# CTRL_MODULE_WKUP register map
Vendor: Texas Instruments
Peripheral module from a debugger description file (folder omap5430_ES2_PUBLIC).
Registers are 32-bit, access per field, reset 0x0 unless marked. A register's access mark holds for its fields unless they carry their own. Offsets are as the file gives them; lines under a group give offsets from that group; [hi:lo] are bit positions; {n}, {i} and the like mark numbered series; 'fields as' and 'values as' point back to an identical list; <NAME> marks a mode.

## CTRL_MODULE_WKUP
0x00 CONTROL_WKUP_REVISION ro reset not defined — Control module revision identifier Access conditions. Read: unrestricted, Write: unrestricted
  [31:0] REVISON — IP Revision . .
0x04 CONTROL_WKUP_HWINFO ro — Information about the IP module hardware configuration i.e. typically the module HDL generics (if any). Access conditions. Read: unrestricted, Write: unrestricted
  [31:0] IP_HWINFO — IP-module dependent
0x10 CONTROL_WKUP_SYSCONFIG reset 0x8 — Access conditions. Read: unrestricted, Write: unrestricted
  [3:2] IP_SYSCONFIG_IDLEMODE rw — RESERVED (not used).
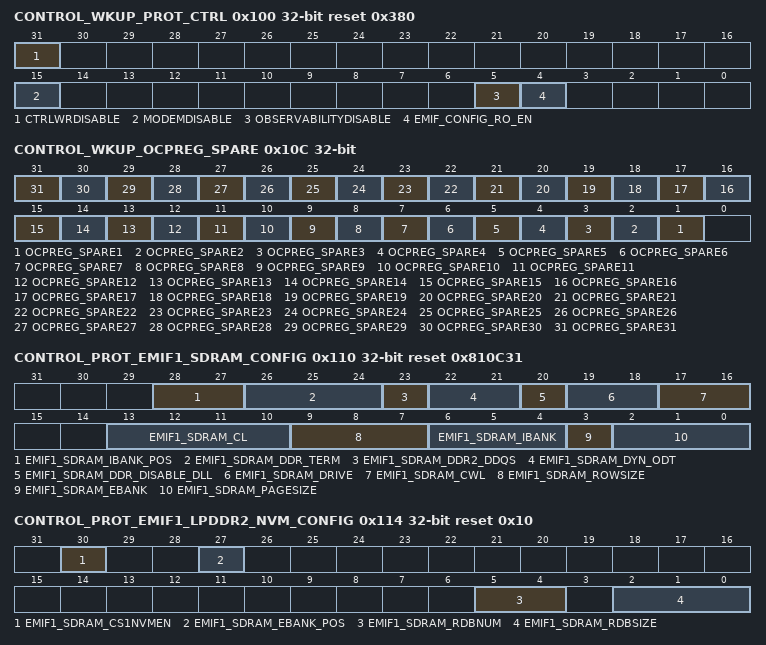
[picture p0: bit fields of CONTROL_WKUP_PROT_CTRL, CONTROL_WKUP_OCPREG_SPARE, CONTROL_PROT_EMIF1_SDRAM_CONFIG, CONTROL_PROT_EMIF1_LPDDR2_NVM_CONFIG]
0x100 CONTROL_WKUP_PROT_CTRL access not given reset 0x380 — Control Register. Access conditions. Read: unrestricted, Write: unrestricted
  [31] CTRLWRDISABLE — Control Register write disable control. (access RW Woco)
    0=wr_allowed (Write in the Control Register is allowed); 1=wr_forbidden (Write in the Control Register is forbidden)
  [15] MODEMDISABLE — Modem enable/disable. When modem functionality has been disabled it is not possible to enable it again without a power-on-reset. (access RW Woco)
    0=modem_enabled (Modem is enabled); 1=modem_disabled (Modem is disabled (forced under reset))
  [5] OBSERVABILITYDISABLE — Control the Observability feature (access RW Woco)
    0=enabled (Observability is enabled.); 1=disabled (Observability is disabled. If pads are configured for the hardware debug, outputs are tied to low)
  [4] EMIF_CONFIG_RO_EN — Access mode for registers: CONTROL_PROT_EMIF1_SDRAM_CONFIG, CONTROL_PROT_EMIF2_SDRAM_CONFIG, CONTROL_PROT_EMIF1_LPDDR2_NVM_CONFIG, CONTROL_PROT_EMIF2_LPDDR2_NVM_CONFIG2 (access RW Woco)
    0=rw (These registers are R/W); 1=ro (These registers are RO)
0x10C CONTROL_WKUP_OCPREG_SPARE — OCP Spare Register Access conditions. Read: unrestricted, Write: unrestricted
  [n] OCPREG_SPARE{n} rw (n=1..31) — OCP spare register {n}
0x110 CONTROL_PROT_EMIF1_SDRAM_CONFIG reset 0x810C31 — EMIF1 SDRAM configuration protection register. Values are exported to EMIF_SDRAM_CONFIG register at POR. For bit field descriptions see EMIF_SDRAM_CONFIG register in, EMIF Controller, in , Memory Subsystem.. Access conditions. Read: unrestricted, Write: If EMIF_CONFIG_RO_EN = 0 (default)
  [28:27] EMIF1_SDRAM_IBANK_POS rw — Internal bank position.
  [26:24] EMIF1_SDRAM_DDR_TERM rw — DDR3 termination resistor value.
  [23] EMIF1_SDRAM_DDR2_DDQS rw — Not used.
  [22:21] EMIF1_SDRAM_DYN_ODT rw — DDR3 Dynamic ODT.
  [20] EMIF1_SDRAM_DDR_DISABLE_DLL rw — Disable DLL select.
  [19:18] EMIF1_SDRAM_DRIVE rw — SDRAM drive strength.
  [17:16] EMIF1_SDRAM_CWL rw — DDR3 CAS Write latency.
  [13:10] EMIF1_SDRAM_CL rw — CAS Latency.
  [9:7] EMIF1_SDRAM_ROWSIZE rw — Row Size.
  [6:4] EMIF1_SDRAM_IBANK rw — Internal Bank setup.
  [3] EMIF1_SDRAM_EBANK rw — External chip select setup.
  [2:0] EMIF1_SDRAM_PAGESIZE rw — Page Size.
0x114 CONTROL_PROT_EMIF1_LPDDR2_NVM_CONFIG reset 0x10 — EMIF1 configuration protection register. Values are exported to EMIF_SDRAM_CONFIG_2 register at POR. For bit field descriptions see EMIF_SDRAM_CONFIG_2 register in, EMIF Controller, in , Memory Subsystem. Access conditions. Read: unrestricted, Write: If EMIF_CONFIG_RO_EN = 0 (default)
  [30] EMIF1_SDRAM_CS1NVMEN rw — CS1 LPDDR2-NVM enable.
  [27] EMIF1_SDRAM_EBANK_POS ro — External bank position. Set to 0 to assign external bank address bits from OCP address. Set to 1 to assign external bank address bits to the most significant bit of the OCP address. This field is not implemented in the design and is resertved fiel for the future use.
  [5:4] EMIF1_SDRAM_RDBNUM rw — Row Buffer setup.
  [2:0] EMIF1_SDRAM_RDBSIZE rw — Row Data Buffer Size.
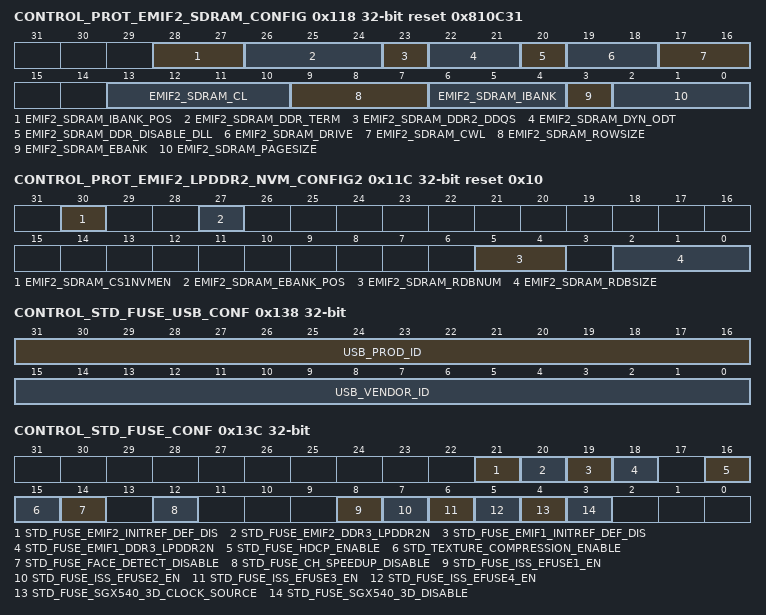
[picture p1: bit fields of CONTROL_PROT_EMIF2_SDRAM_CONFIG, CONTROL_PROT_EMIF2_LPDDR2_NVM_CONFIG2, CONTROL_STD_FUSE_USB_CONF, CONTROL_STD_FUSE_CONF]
0x118 CONTROL_PROT_EMIF2_SDRAM_CONFIG reset 0x810C31 — EMIF2 SDRAM configuration protection register. Values are exported to EMIF_SDRAM_CONFIG register at POR. For bit field descriptions see EMIF_SDRAM_CONFIG register in, EMIF Controller, in , Memory Subsystem. Access conditions. Read: unrestricted, Write: EMIF_CONFIG_RO_EN = 0 (default)
  [28:27] EMIF2_SDRAM_IBANK_POS rw — Internal bank position.
  [26:24] EMIF2_SDRAM_DDR_TERM rw — DDR3 termination resistor value.
  [23] EMIF2_SDRAM_DDR2_DDQS rw — Not used.
  [22:21] EMIF2_SDRAM_DYN_ODT rw — DDR3 Dynamic ODT.
  [20] EMIF2_SDRAM_DDR_DISABLE_DLL rw — Disable DLL select.
  [19:18] EMIF2_SDRAM_DRIVE rw — SDRAM drive strength.
  [17:16] EMIF2_SDRAM_CWL rw — DDR3 CAS Write latency.
  [13:10] EMIF2_SDRAM_CL rw — CAS Latency.
  [9:7] EMIF2_SDRAM_ROWSIZE rw — Row Size.
  [6:4] EMIF2_SDRAM_IBANK rw — Internal Bank setup.
  [3] EMIF2_SDRAM_EBANK rw — External chip select setup.
  [2:0] EMIF2_SDRAM_PAGESIZE rw — Page Size.
0x11C CONTROL_PROT_EMIF2_LPDDR2_NVM_CONFIG2 reset 0x10 — EMIF2 configuration protection register. Values are exported to EMIF_SDRAM_CONFIG_2 register at POR. For bit field descriptions see EMIF_SDRAM_CONFIG_2 register in, EMIF Controller, in , Memory Subsystem. Access conditions. Read: unrestricted, Write: EMIF_CONFIG_RO_EN = 0 (default)
  [30] EMIF2_SDRAM_CS1NVMEN rw — CS1 LPDDR2-NVM enable.
  [27] EMIF2_SDRAM_EBANK_POS ro — External bank position. Set to 0 to assign external bank address bits from OCP address. Set to 1 to assign external bank address bits to the most significant bit of the OCP address. This field is not implemented in the design and is resertved fiel for the future use.
  [5:4] EMIF2_SDRAM_RDBNUM rw — Row Buffer setup.
  [2:0] EMIF2_SDRAM_RDBSIZE rw — Row Data Buffer Size.
0x138 CONTROL_STD_FUSE_USB_CONF ro — Standard Fuse conf [31:0]. Register shows part of the chip eFuse configuration on the OCP interface. Reading at the address of one of these registers provides a direct view into a part of the eFuse chain. Access conditions. Read: unrestricted, Write: unrestricted
  [31:16] USB_PROD_ID — USB Product Identification
  [15:0] USB_VENDOR_ID — USB Vendor Identification
0x13C CONTROL_STD_FUSE_CONF ro reset not defined — Standard Fuse conf [63:32]. Register shows part of the chip eFuse configuration. Reading at the address of one of these registers provides a direct view into a part of the eFuse chain. Access conditions. Read Only.
  [21] STD_FUSE_EMIF2_INITREF_DEF_DIS — EMIF2 disable EMIF DDR refresh and init sequence
    1=disabled (refresh and init sequence are disabled); 0=enabled (refresh and init sequence are enabled)
  [20] STD_FUSE_EMIF2_DDR3_LPDDR2N — EMIF2 DDR3 or LPDDR2
    1=DDR3 configured; 0=LPDDR2 configured
  [19] STD_FUSE_EMIF1_INITREF_DEF_DIS — EMIF1 disable EMIF DDR refresh and init sequence
    values as STD_FUSE_EMIF2_INITREF_DEF_DIS
  [18] STD_FUSE_EMIF1_DDR3_LPDDR2N — EMIF1 DDR3 or LPDDR2
    1=DDR3 configured; 0=LPDDR2 configured
  [16] STD_FUSE_HDCP_ENABLE — Enable HDCP
    1=disabled (HDCP is disabled); 0=enabled (HDCP is enabled)
  [15] STD_TEXTURE_COMPRESSION_ENABLE — Disable texture compression(note: this bit is inverted compared to its eFuse)
    1=enabled (texture compression is enabled); 0=disabled (texture compression is disabled)
  [14] STD_FUSE_FACE_DETECT_DISABLE — Disable face detect
    1=disabled (face detect is disabled); 0=enabled (face detect is enabled)
  [12] STD_FUSE_CH_SPEEDUP_DISABLE — ROM code settings for configuration header block. Only SW access.
    1=disabled (CH is disabled); 0=enabled (CH is enabled)
  [9-n] STD_FUSE_ISS_EFUSE{n}_EN (n=1..4) — Enable implementation specific features.
    1=enabled (specific features are enabled); 0=disabled (specific features are disabled)
  [4] STD_FUSE_SGX540_3D_CLOCK_SOURCE — Functional clock selection for the 3D accelerator engine
    0=fully_enabled (GPU is fully enabled (DPLL_CORE/PER)); 1=partially_enabled (GPU is partially enabled (DPLL_PER/8 max))
  [3] STD_FUSE_SGX540_3D_DISABLE — Disable the 3D accelerator engine
    1=disabled (SGX is disabled); 0=enabled (SGX is enabled)
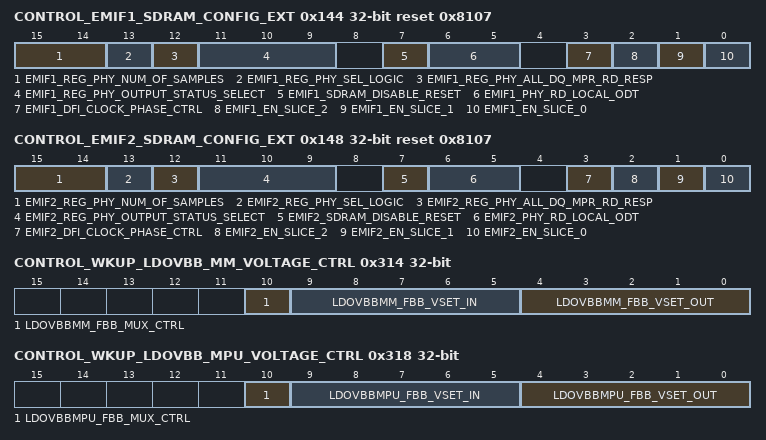
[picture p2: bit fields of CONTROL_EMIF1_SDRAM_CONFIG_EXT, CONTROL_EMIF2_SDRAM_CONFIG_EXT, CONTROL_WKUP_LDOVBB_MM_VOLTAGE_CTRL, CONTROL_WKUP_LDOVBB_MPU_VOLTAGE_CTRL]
0x144 CONTROL_EMIF1_SDRAM_CONFIG_EXT reset 0x8107 — PHY register for EMIF1 Access conditions. Read: unrestricted, Write: unrestricted
  [15:14] EMIF1_REG_PHY_NUM_OF_SAMPLES rw — Controls the number of DQ samples required for read leveling. The recommended setting for full leveling is 0x3 (128 samples) and for incremental leveling is 0x0 (4 samples).
    0=4_samples; 1=8_samples; 2=16_samples; 3=128_samples
  [13] EMIF1_REG_PHY_SEL_LOGIC rw — Selects an algorithm for read leveling. The use of algorithm 1 (set by default) is recommended.
    0=Algorithm 1 is used; 1=Algorithm 2 is used
  [12] EMIF1_REG_PHY_ALL_DQ_MPR_RD_RESP rw — Analysis method of DQ bits during read leveling.
    0=if_one_DQ_bit_response (if the DRAM provides a read response on only one DQ bit. This is the default setting and works with all memory types (memories send responses on all DQ bits or on a single DQ bit).); 1=if_all_DQ_bits_response (if the DRAM provides a read response on all DQ bits.)
  [11:9] EMIF1_REG_PHY_OUTPUT_STATUS_SELECT rw — Selects the status to be observed on the outputs of the DDR PHYs throughCONTROL_EMIF1_SDRAM_CONFIG_EXT_1 register.
    0=rdlvl_start_ratio[7:0] (selects phy_reg_rdlvl_start_ratio[7:0]); 1=rdlvl_start_ratio[15:8] (selects phy_reg_rdlvl_start_ratio[15:8]); 2=rdlvl_end_ratio[7:0] (selects phy_reg_rdlvl_end_ratio[7:0]); 3=rdlvl_end_ratio[15:8] (selects phy_reg_rdlvl_end_ratio[15:8])
  [7] EMIF1_SDRAM_DISABLE_RESET rw — ddr3ch1_nreset signal disable. Keep this bit set to 0x1 during normal operations and to 0x0 at boot time and when a memory reset is necessary.
    0=enable_DDR3_nreset (ddr3ch1_nreset is enabled. It can be asserted by EMIF.); 1=disable_DDR3_nreset (ddr3ch1_nreset is disabled. It is forbidden to EMIF to assert it.)
  [6:5] EMIF1_PHY_RD_LOCAL_ODT rw — Control of ODT (on – die termination) settings for the device DDR I/Os. ODT is enabled only during read operations when termination is required.
    0=disable_ODT (ODT disabled.); 1=ODT_60_Ohms (60 Ohms.); 2=ODT_80_Ohms (80 Ohms.); 3=ODT_120_Ohms (120 Ohms.)
  [3] EMIF1_DFI_CLOCK_PHASE_CTRL rw — EMIF_CORE1 clock phase control (shifting by 180°). For normal operation this bit must always be set to 0x0 (disabled).
  [2] EMIF1_EN_SLICE_2 rw — Enable command PHY 2. 0x1 is the mandatory setting if LPDDR2 is used. When using DDR3 this bit can be set to 0x0 or 0x1. For lower power consumption 0x0 is used.
  [1] EMIF1_EN_SLICE_1 rw — Enable command PHY 1. 0x1 is the mandatory setting if DDR3 is used. When using LPDDR2 this bit can be set to 0x0 or 0x1. For lower power consumption 0x0 is used. EMIF1_EN_SLICE_0 and EMIF1_EN_SLICE_1 have to be programmed with the same value.
  [0] EMIF1_EN_SLICE_0 rw — Enable command PHY 0. 0x1 is the mandatory setting if DDR3 is used. When using LPDDR2 this bit can be set to 0x0 or 0x1. For lower power consumption 0x0 is used. EMIF1_EN_SLICE_0 and EMIF1_EN_SLICE_1 have to be programmed with the same value.
0x148 CONTROL_EMIF2_SDRAM_CONFIG_EXT reset 0x8107 — PHY register for EMIF2 Access conditions. Read: unrestricted, Write: unrestricted
  [15:14] EMIF2_REG_PHY_NUM_OF_SAMPLES rw — Controls the number of DQ samples required for read leveling. The recommended setting for full leveling is 0x3 (128 samples) and for incremental leveling is 0x0 (4 samples).
    0=4_samples; 1=8_samples; 2=16_samples; 3=128_samples
  [13] EMIF2_REG_PHY_SEL_LOGIC rw — Selects an algorithm for read leveling. The use of algorithm 1 (set by default) is recommended.
    0=Algorithm 1 is used; 1=Algorithm 2 is used
  [12] EMIF2_REG_PHY_ALL_DQ_MPR_RD_RESP rw — Analysis method of DQ bits during read leveling.
    values as CONTROL_EMIF1_SDRAM_CONFIG_EXT.EMIF1_REG_PHY_ALL_DQ_MPR_RD_RESP
  [11:9] EMIF2_REG_PHY_OUTPUT_STATUS_SELECT rw — Selects the status to be observed on the outputs of the DDR PHYs throughCONTROL_EMIF2_SDRAM_CONFIG_EXT_2 register.
    values as CONTROL_EMIF1_SDRAM_CONFIG_EXT.EMIF1_REG_PHY_OUTPUT_STATUS_SELECT
  [7] EMIF2_SDRAM_DISABLE_RESET rw — ddr3ch2_nreset signal disable. Keep this bit set to 0x1 during normal operations and to 0x0 at boot time and when a memory reset is necessary.
    0=enable_DDR3_nreset (ddr3ch2_nreset is enabled. It can be asserted by EMIF.); 1=disable_DDR3_nreset (ddr3ch2_nreset is disabled. It is forbidden to EMIF to assert it.)
  [6:5] EMIF2_PHY_RD_LOCAL_ODT rw — Control of ODT (on – die termination) settings for the device DDR I/Os. ODT is enabled only during read operations when termination is required.
    values as CONTROL_EMIF1_SDRAM_CONFIG_EXT.EMIF1_PHY_RD_LOCAL_ODT
  [3] EMIF2_DFI_CLOCK_PHASE_CTRL rw — EMIF_CORE2 clock phase control (shifting by 180°). For normal operation this bit must always be set to 0x0 (disabled).
  [2] EMIF2_EN_SLICE_2 rw — Enable command PHY 2. 0x1 is the mandatory setting if LPDDR2 is used. When using DDR3 this bit can be set to 0x0 or 0x1. For lower power consumption 0x0 is used.
  [1] EMIF2_EN_SLICE_1 rw — Enable command PHY 1. 0x1 is the mandatory setting if DDR3 is used. When using LPDDR2 this bit can be set to 0x0 or 0x1. For lower power consumption 0x0 is used. EMIF2_EN_SLICE_0 and EMIF2_EN_SLICE_1 have to be programmed with the same value.
  [0] EMIF2_EN_SLICE_0 rw — Enable command PHY 0. 0x1 is the mandatory setting if DDR3 is used. When using LPDDR2 this bit can be set to 0x0 or 0x1. For lower power consumption 0x0 is used. EMIF2_EN_SLICE_0 and EMIF2_EN_SLICE_1 have to be programmed with the same value.
0x14C CONTROL_EMIF1_SDRAM_CONFIG_EXT_1 ro — Access conditions. Read: unrestricted, Write: unrestricted
  [31:0] EMIF1_PHY_REG_READ_DATA_EYE_LVL
0x150 CONTROL_EMIF2_SDRAM_CONFIG_EXT_2 ro — Access conditions. Read: unrestricted, Write: unrestricted
  [31:0] EMIF2_PHY_REG_READ_DATA_EYE_LVL
0x200 CONTROL_WKUP_STD_FUSE_DIE_ID_0 ro — Die ID Register - Part 0. Register shows part of the chip eFuse configuration on the OCP interface. Reading at the address of one of these registers provides a direct view into a part of the eFuse chain. Access conditions. Read: unrestricted, Write: unrestricted
  [31:0] STD_FUSE_DIE_ID_0
0x204 CONTROL_WKUP_ID_CODE ro — Key Register Access conditions. Read: unrestricted, Write: unrestricted
  [31:0] STD_FUSE_IDCODE
{0x204+4i} CONTROL_WKUP_STD_FUSE_DIE_ID_{i} ro (i=1..3) — Die ID Register - Part {i}. Register shows part of the chip eFuse configuration on the OCP interface. Reading at the address of one of these registers provides a direct view into a part of the eFuse chain. Access conditions. Read: unrestricted, Write: unrestricted
  [31:0] STD_FUSE_DIE_ID_{i}
0x214 CONTROL_WKUP_STD_FUSE_PROD_ID_0 ro — Prod ID Register - Part 0. Register shows part of the chip eFuse configuration on the OCP interface. Reading at the address of one of these registers provides a direct view into a part of the eFuse chain. Access conditions. Read: unrestricted, Write: unrestricted
  [31:0] STD_FUSE_PROD_ID
0x314 CONTROL_WKUP_LDOVBB_MM_VOLTAGE_CTRL — MM Voltage Body Bias LDO Control register Access conditions. Read: unrestricted, Write: unrestricted
  [10] LDOVBBMM_FBB_MUX_CTRL rw — Override control of EFUSE Forward Body Bias voltage value
    0=efuse value is used; 1=ocp (override value is used)
  [9:5] LDOVBBMM_FBB_VSET_IN ro — EFUSE Forward Body Bias voltage value
  [4:0] LDOVBBMM_FBB_VSET_OUT rw — Override value for Forward Body Bias voltage
0x318 CONTROL_WKUP_LDOVBB_MPU_VOLTAGE_CTRL — MPU Voltage Body Bias LDO Control register Access conditions. Read: unrestricted, Write: unrestricted
  [10] LDOVBBMPU_FBB_MUX_CTRL rw — Override control of EFUSE Forward Body Bias voltage value
    0=efuse value is used; 1=ocp (override value is used)
  [9:5] LDOVBBMPU_FBB_VSET_IN ro — EFUSE Forward Body Bias voltage value
  [4:0] LDOVBBMPU_FBB_VSET_OUT rw — Override value for Forward Body Bias voltage
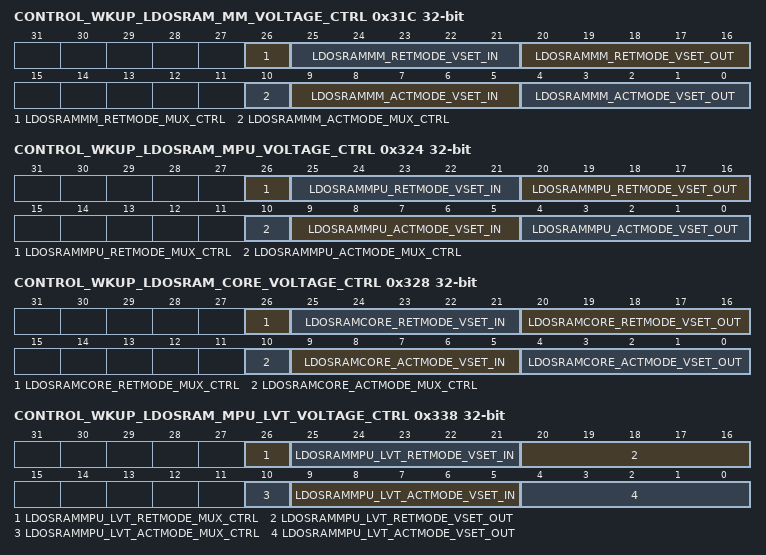
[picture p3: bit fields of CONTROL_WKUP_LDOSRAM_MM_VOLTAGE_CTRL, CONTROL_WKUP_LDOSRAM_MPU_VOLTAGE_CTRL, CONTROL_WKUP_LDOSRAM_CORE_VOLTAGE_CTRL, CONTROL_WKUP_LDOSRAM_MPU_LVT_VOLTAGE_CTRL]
0x31C CONTROL_WKUP_LDOSRAM_MM_VOLTAGE_CTRL — IVA SRAM LDO Control register Access conditions. Read: unrestricted, Write: unrestricted
  [26] LDOSRAMMM_RETMODE_MUX_CTRL rw — Override control of EFUSE Retention Mode Voltage value
    0=efuse value is used; 1=ocp (override value is used)
  [25:21] LDOSRAMMM_RETMODE_VSET_IN ro — EFUSE Retention Mode Voltage value (vset[9:5])
  [20:16] LDOSRAMMM_RETMODE_VSET_OUT rw — Override value for Retention Mode Voltage
  [10] LDOSRAMMM_ACTMODE_MUX_CTRL rw — Override control of EFUSE Active Mode Voltage value
    0=efuse value is used; 1=ocp (override value is used)
  [9:5] LDOSRAMMM_ACTMODE_VSET_IN ro — EFUSE Active Mode Voltage value (vset[4:0])
  [4:0] LDOSRAMMM_ACTMODE_VSET_OUT rw — Override value for Active Mode Voltage value
0x324 CONTROL_WKUP_LDOSRAM_MPU_VOLTAGE_CTRL — MPU SRAM LDO Control register Access conditions. Read: unrestricted, Write: unrestricted
  [26] LDOSRAMMPU_RETMODE_MUX_CTRL rw — Override control of EFUSE Retention Mode Voltage value
    0=efuse value is used; 1=ocp (override value is used)
  [25:21] LDOSRAMMPU_RETMODE_VSET_IN ro — EFUSE Retention Mode Voltage value (vset[9:5])
  [20:16] LDOSRAMMPU_RETMODE_VSET_OUT rw — Override value for Retention Mode Voltage
  [10] LDOSRAMMPU_ACTMODE_MUX_CTRL rw — Override control of EFUSE Active Mode Voltage value
    0=efuse value is used; 1=ocp (override value is used)
  [9:5] LDOSRAMMPU_ACTMODE_VSET_IN ro — EFUSE Active Mode Voltage value (vset[4:0])
  [4:0] LDOSRAMMPU_ACTMODE_VSET_OUT rw — Override value for Active Mode Voltage value
0x328 CONTROL_WKUP_LDOSRAM_CORE_VOLTAGE_CTRL — Core SRAM LDO Control register Access conditions. Read: unrestricted, Write: unrestricted
  [26] LDOSRAMCORE_RETMODE_MUX_CTRL rw — Override control of EFUSE Retention Mode Voltage value
    0=efuse value is used; 1=ocp (override value is used)
  [25:21] LDOSRAMCORE_RETMODE_VSET_IN ro — EFUSE Retention Mode Voltage value (vset[9:5])
  [20:16] LDOSRAMCORE_RETMODE_VSET_OUT rw — Override value for Retention Mode Voltage
  [10] LDOSRAMCORE_ACTMODE_MUX_CTRL rw — Override control of EFUSE Active Mode Voltage value
    0=efuse value is used; 1=ocp (override value is used)
  [9:5] LDOSRAMCORE_ACTMODE_VSET_IN ro — EFUSE Active Mode Voltage value (vset[4:0])
  [4:0] LDOSRAMCORE_ACTMODE_VSET_OUT rw — Override value for Active Mode Voltage value
0x338 CONTROL_WKUP_LDOSRAM_MPU_LVT_VOLTAGE_CTRL — MPU LVT SRAM LDO Control register Access conditions. Read: unrestricted, Write: unrestricted
  [26] LDOSRAMMPU_LVT_RETMODE_MUX_CTRL rw — Override control of EFUSE Retention Mode Voltage value
    0=efuse value is used; 1=ocp (override value is used)
  [25:21] LDOSRAMMPU_LVT_RETMODE_VSET_IN ro — EFUSE Retention Mode Voltage value (vset[9:5])
  [20:16] LDOSRAMMPU_LVT_RETMODE_VSET_OUT rw — Override value for Retention Mode Voltage
  [10] LDOSRAMMPU_LVT_ACTMODE_MUX_CTRL rw — Override control of EFUSE Active Mode Voltage value
    0=efuse value is used; 1=ocp (override value is used)
  [9:5] LDOSRAMMPU_LVT_ACTMODE_VSET_IN ro — EFUSE Active Mode Voltage value (vset[4:0])
  [4:0] LDOSRAMMPU_LVT_ACTMODE_VSET_OUT rw — Override value for Active Mode Voltage value
0x460 CONTROL_WKUP_CONF_DEBUG_SEL_TST_0 — Select mode for debug port Access conditions. Read: unrestricted, Write: unrestricted
  [1:0] MODE rw — Select one of the following signals :
    0=MODE_I0 (hwobs_int_prm_0); 1=MODE_I1 (hwobs_int_cm1_0); 3=MODE_I3 (hwobs_debug_abe_0); 2=MODE_I2 (hwobs_abe_irq)
{0x460+4i} CONTROL_WKUP_CONF_DEBUG_SEL_TST_{i} (i=1..31) — Select mode for debug port Access conditions. Read: unrestricted, Write: unrestricted
  [1:0] MODE rw — Select one of the following signals :
    0=MODE_I0 (hwobs_int_prm_{i}); 1=MODE_I1 (hwobs_int_cm1_{i}); 3=MODE_I3 (hwobs_debug_abe_{i}); 2=MODE_I2 ('0')
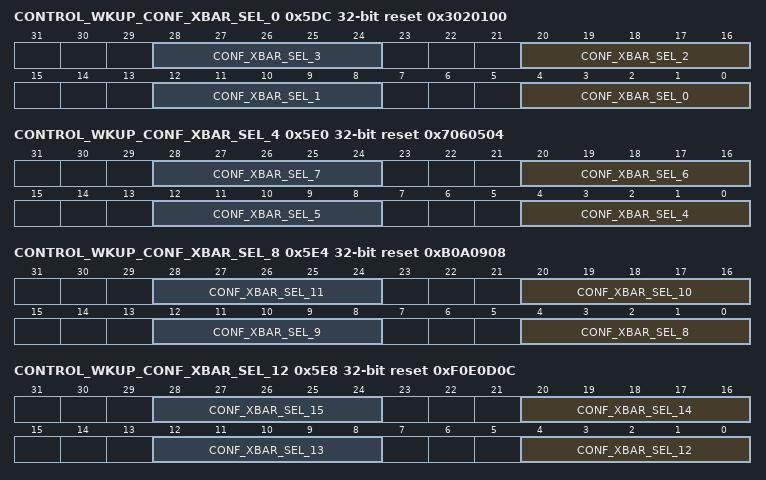
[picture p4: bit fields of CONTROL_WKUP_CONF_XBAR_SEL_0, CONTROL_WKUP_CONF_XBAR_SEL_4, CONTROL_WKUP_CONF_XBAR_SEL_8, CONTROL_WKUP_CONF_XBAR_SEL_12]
0x5DC CONTROL_WKUP_CONF_XBAR_SEL_0 reset 0x3020100 — Access conditions. Read: unrestricted, Write: unrestricted
  [8n+4:8n] CONF_XBAR_SEL_{n} rw (n=0..3) — Select for xbar test_port_{n}
0x5E0 CONTROL_WKUP_CONF_XBAR_SEL_4 reset 0x7060504 — Access conditions. Read: unrestricted, Write: unrestricted
  [8n-28:8n-32] CONF_XBAR_SEL_{n} rw (n=4..7) — Select for xbar test_port_{n}
0x5E4 CONTROL_WKUP_CONF_XBAR_SEL_8 reset 0xB0A0908 — Access conditions. Read: unrestricted, Write: unrestricted
  [8n-60:8n-64] CONF_XBAR_SEL_{n} rw (n=8..11) — Select for xbar test_port_{n}
0x5E8 CONTROL_WKUP_CONF_XBAR_SEL_12 reset 0xF0E0D0C — Access conditions. Read: unrestricted, Write: unrestricted
  [8n-92:8n-96] CONF_XBAR_SEL_{n} rw (n=12..15) — Select for xbar test_port_{n}
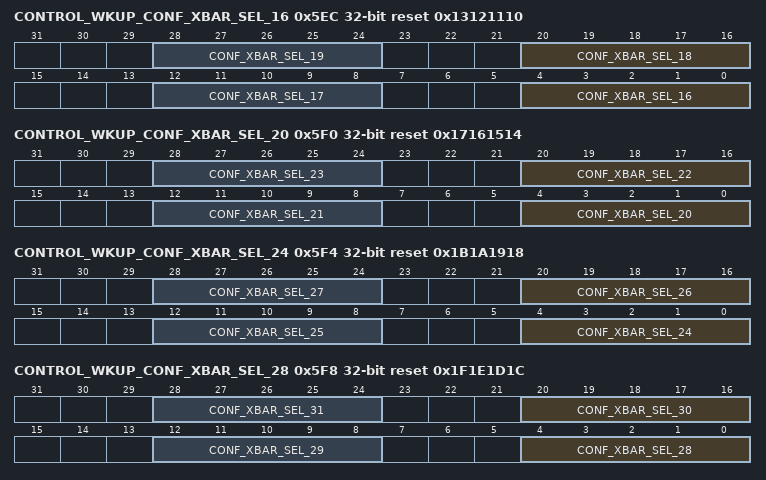
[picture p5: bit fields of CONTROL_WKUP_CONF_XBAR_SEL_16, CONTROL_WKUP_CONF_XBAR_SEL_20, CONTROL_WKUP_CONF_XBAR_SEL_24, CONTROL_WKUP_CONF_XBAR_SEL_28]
0x5EC CONTROL_WKUP_CONF_XBAR_SEL_16 reset 0x13121110 — Access conditions. Read: unrestricted, Write: unrestricted
  [8n-124:8n-128] CONF_XBAR_SEL_{n} rw (n=16..19) — Select for xbar test_port_{n}
0x5F0 CONTROL_WKUP_CONF_XBAR_SEL_20 reset 0x17161514 — Access conditions. Read: unrestricted, Write: unrestricted
  [8n-156:8n-160] CONF_XBAR_SEL_{n} rw (n=20..23) — Select for xbar test_port_{n}
0x5F4 CONTROL_WKUP_CONF_XBAR_SEL_24 reset 0x1B1A1918 — Access conditions. Read: unrestricted, Write: unrestricted
  [8n-188:8n-192] CONF_XBAR_SEL_{n} rw (n=24..27) — Select for xbar test_port_{n}
0x5F8 CONTROL_WKUP_CONF_XBAR_SEL_28 reset 0x1F1E1D1C — Access conditions. Read: unrestricted, Write: unrestricted
  [8n-220:8n-224] CONF_XBAR_SEL_{n} rw (n=28..31) — Select for xbar test_port_{n}
0x5FC CONTROL_WKUP_CONF_XBAR_BYPASS reset 0x1 — Crossbar bypass control register Access conditions. Read: unrestricted, Write: unrestricted
  [0] SELECT rw — Crossbar enable/disable
    0=enable_crossbar (Crossbar is enabled); 1=disable_crossbar (Crossbar is disabled (bypassed))
